VERSION ""

NS_ :

BS_:

BU_:

BO_ 0 message0: 8 Vector__XXX
	SG_ signal0 : 0|8@1+ (1,0) [0|256] "unit0" Vector__XXX

BO_ 2 message2: 8 Vector__XXX
	SG_ signal0 : 0|8@1+ (1,0) [0|256] "unit0" Vector__XXX
    SG_ signal1 : 8|8@1+ (1,0) [0|256] "unit1" Vector__XXX

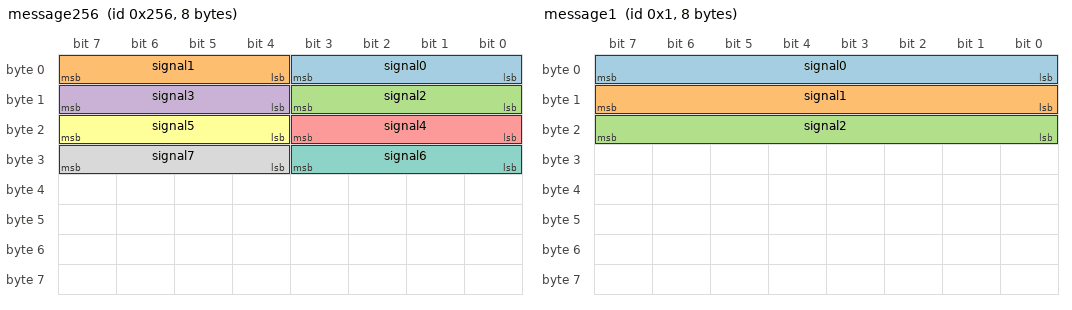
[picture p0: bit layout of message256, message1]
BO_ 598 message256: 8 Vector__XXX
	SG_ signal0 : 0|4@1+ (1,0) [0|256] "unit0" Vector__XXX
	SG_ signal1 : 4|4@1+ (1,0) [0|256] "unit1" Vector__XXX
	SG_ signal2 : 8|4@1+ (1,0) [0|256] "unit2" Vector__XXX
	SG_ signal3 : 12|4@1+ (1,0) [0|256] "unit3" Vector__XXX
	SG_ signal4 : 16|4@1+ (1,0) [0|256] "unit4" Vector__XXX
	SG_ signal5 : 20|4@1+ (1,0) [0|256] "unit5" Vector__XXX
	SG_ signal6 : 24|4@1+ (1,0) [0|256] "unit6" Vector__XXX
	SG_ signal7 : 28|4@1+ (1,0) [0|256] "unit7" Vector__XXX

BO_ 1 message1: 8 Vector__XXX
	SG_ signal0 : 0|8@1+ (1,0) [0|256] "unit0" Vector__XXX
	SG_ signal1 : 8|8@1+ (1,0) [0|256] "unit1" Vector__XXX
	SG_ signal2 : 16|8@1+ (1,0) [0|256] "unit2" Vector__XXX

CM_ BO_ 0 "comment 0";
CM_ SG_ 0 signal0 "signal0 comment";
CM_ BO_ 2 "comment 2";
CM_ SG_ 2 signal0 "signal0 comment";
CM_ SG_ 2 signal1 "signal1 comment";
CM_ BO_ 598 "comment 256";
CM_ SG_ 598 signal0 "signal0 comment";
CM_ SG_ 598 signal1 "signal1 comment";
CM_ SG_ 598 signal2 "signal2 comment";
CM_ SG_ 598 signal3 "signal3 comment";
CM_ SG_ 598 signal4 "signal4 comment";
CM_ SG_ 598 signal5 "signal5 comment";
CM_ SG_ 598 signal6 "signal6 comment";
CM_ SG_ 598 signal7 "signal7 comment";
CM_ BO_ 1 "comment 1";
CM_ SG_ 1 signal0 "signal0 comment";
BA_DEF_ SG_  "SPN" INT 0 524287;
BA_DEF_ BO_  "VFrameFormat" ENUM  "StandardCAN","ExtendedCAN","reserved","J1939PG";
BA_DEF_  "DatabaseVersion" STRING ;
BA_DEF_  "BusType" STRING ;
BA_DEF_  "ProtocolType" STRING ;
BA_DEF_  "DatabaseCompiler" STRING ;
BA_DEF_DEF_  "SPN" 0;
BA_DEF_DEF_  "VFrameFormat" "J1939PG";
BA_DEF_DEF_  "DatabaseVersion" "DEMO PLUS";
BA_DEF_DEF_  "BusType" "";
BA_DEF_DEF_  "ProtocolType" "";
BA_DEF_DEF_  "DatabaseCompiler" "";
BA_ "ProtocolType" "J1939";
BA_ "BusType" "CAN";
BA_ "DatabaseCompiler" "CSS ELECTRONICS (WWW.CSSELECTRONICS.COM)";
BA_ "DatabaseVersion" "1.0.0";
BA_ "SPN" SG_ 0 WheelBasedVehicleSpeed 84;
